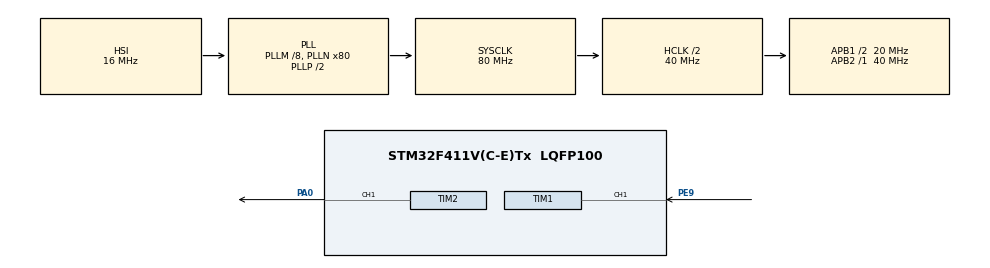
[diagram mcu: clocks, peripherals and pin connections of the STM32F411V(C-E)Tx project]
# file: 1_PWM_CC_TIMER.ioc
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Mcu.Family=STM32F4
PC15-OSC32_OUT.Mode=LSE-External-Oscillator
RCC.CortexFreq_Value=40000000
RCC.APB1CLKDivider=RCC_HCLK_DIV2
PC14-OSC32_IN.Signal=RCC_OSC32_IN
RCC.SYSCLKSource=RCC_SYSCLKSOURCE_PLLCLK
ProjectManager.StackSize=0x400
PA0-WKUP.Signal=S_TIM2_CH1_ETR
TIM2.Pulse-PWM\ Generation1\ CH1=500
PA13.Signal=SYS_JTMS-SWDIO
TIM1.Prescaler=40
SH.S_TIM1_CH1.0=TIM1_CH1,Input_Capture1_from_TI1
ProjectManager.TargetToolchain=STM32CubeIDE
RCC.HCLKFreq_Value=40000000
RCC.APB2TimFreq_Value=40000000
PC15-OSC32_OUT.Signal=RCC_OSC32_OUT
RCC.AHBFreq_Value=40000000
RCC.HSE_VALUE=8000000
board=STM32F411E-DISCO
RCC.VCOOutputFreq_Value=160000000
RCC.APB2Freq_Value=40000000
PC14-OSC32_IN.Mode=LSE-External-Oscillator
VP_TIM2_VS_ClockSourceINT.Mode=Internal
PE9.Signal=S_TIM1_CH1
PA14.Mode=Serial_Wire
RCC.AHBCLKDivider=RCC_SYSCLK_DIV2
TIM2.Channel-PWM\ Generation1\ CH1=TIM_CHANNEL_1
TIM2.Period=999
PA13.Mode=Serial_Wire
Mcu.Name=STM32F411V(C-E)Tx
VP_TIM1_VS_ClockSourceINT.Mode=Internal
NVIC.TIM1_CC_IRQn=true\:0\:0\:false\:false\:true\:true\:true
RCC.48MHZClocksFreq_Value=20000000
RCC.SYSCLKFreq_VALUE=80000000
Mcu.Package=LQFP100
TIM2.Prescaler=0
TIM1.Channel-Input_Capture1_from_TI1=TIM_CHANNEL_1
SH.S_TIM2_CH1_ETR.0=TIM2_CH1,PWM Generation1 CH1
PA14.Signal=SYS_JTCK-SWCLK
ProjectManager.HeapSize=0x200
RCC.HSI_VALUE=16000000
RCC.PLLQ=8
NVIC.PriorityGroup=NVIC_PRIORITYGROUP_0
RCC.PLLM=8
RCC.PLLN=80
RCC.APB1TimFreq_Value=40000000
TIM1.ICPolarity_CH1=TIM_INPUTCHANNELPOLARITY_FALLING
TIM1.Period=0xffff
RCC.APB1Freq_Value=20000000
RCC.PLLI2SN=200
RCC.PLLI2SM=5

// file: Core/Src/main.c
/* USER CODE BEGIN Header */
/**
  ******************************************************************************
  * @file           : main.c
  * @brief          : Main program body
  ******************************************************************************
  * @attention
  *
  * <h2><center>&copy; Copyright (c) 2021 STMicroelectronics.
  * All rights reserved.</center></h2>
  *
  * This software component is licensed by ST under Ultimate Liberty license
  * SLA0044, the "License"; You may not use this file except in compliance with
  * the License. You may obtain a copy of the License at:
  *                             www.st.com/SLA0044
  *
  ******************************************************************************
  */
/* USER CODE END Header */
#include "main.h"

TIM_HandleTypeDef htim1;
TIM_HandleTypeDef htim2;

/* USER CODE BEGIN PV */
	uint16_t icValue = 0;
	uint16_t preIcValue = 0;
	uint16_t T = 0;
	uint16_t f = 0;
	uint8_t firstEdge = 0;
/* USER CODE END PV */

void SystemClock_Config(void);
static void MX_GPIO_Init(void);
static void MX_TIM1_Init(void);
static void MX_TIM2_Init(void);

/* USER CODE BEGIN 0 */
void HAL_TIM_IC_CaptureCallback(TIM_HandleTypeDef *htim)
{
	icValue = __HAL_TIM_GET_COMPARE(&htim1,TIM_CHANNEL_1);
	if(firstEdge ==0 )
	{
		preIcValue = icValue;
		firstEdge++;
	}
	else if(firstEdge == 1)
	{
		T = icValue - preIcValue;
		f = 1000000/T;
		firstEdge = 0;
		HAL_TIM_IC_Stop_IT(&htim1, TIM_CHANNEL_1);
	}

//	preIcValue = icValue;
	//1MHZ clock = > T xung => t us
}
void dutyScale()
{
	//1Khz => 1% <=> 10
	for(unsigned short duty = 0; duty <= 100; duty++)
	{
		__HAL_TIM_SET_COMPARE(&htim2,TIM_CHANNEL_1,10*duty);
		HAL_Delay(100);
	}
}
void getPulseFreq()
{
	  HAL_TIM_IC_Start_IT(&htim1, TIM_CHANNEL_1);
}
/* USER CODE END 0 */

int main(void)
{

  /* MCU Configuration--------------------------------------------------------*/

  /* Reset of all peripherals, Initializes the Flash interface and the Systick. */
  HAL_Init();

  /* Configure the system clock */
  SystemClock_Config();

  /* Initialize all configured peripherals */
  MX_GPIO_Init();
  MX_TIM1_Init();
  MX_TIM2_Init();
  /* USER CODE BEGIN 2 */
  HAL_TIM_PWM_Start(&htim2, TIM_CHANNEL_1);
  HAL_TIM_IC_Start_IT(&htim1, TIM_CHANNEL_1);
  /* USER CODE END 2 */

  /* Infinite loop */
  while (1)
  {

  }
}

void SystemClock_Config(void)
{
  RCC_OscInitTypeDef RCC_OscInitStruct = {0};
  RCC_ClkInitTypeDef RCC_ClkInitStruct = {0};

  /** Configure the main internal regulator output voltage
  */
  __HAL_RCC_PWR_CLK_ENABLE();
  __HAL_PWR_VOLTAGESCALING_CONFIG(PWR_REGULATOR_VOLTAGE_SCALE1);
  /** Initializes the RCC Oscillators according to the specified parameters
  * in the RCC_OscInitTypeDef structure.
  */
  RCC_OscInitStruct.OscillatorType = RCC_OSCILLATORTYPE_HSI;
  RCC_OscInitStruct.HSIState = RCC_HSI_ON;
  RCC_OscInitStruct.HSICalibrationValue = RCC_HSICALIBRATION_DEFAULT;
  RCC_OscInitStruct.PLL.PLLState = RCC_PLL_ON;
  RCC_OscInitStruct.PLL.PLLSource = RCC_PLLSOURCE_HSI;
  RCC_OscInitStruct.PLL.PLLM = 8;
  RCC_OscInitStruct.PLL.PLLN = 80;
  RCC_OscInitStruct.PLL.PLLP = RCC_PLLP_DIV2;
  RCC_OscInitStruct.PLL.PLLQ = 8;
  if (HAL_RCC_OscConfig(&RCC_OscInitStruct) != HAL_OK)
  {
    Error_Handler();
  }
  /** Initializes the CPU, AHB and APB buses clocks
  */
  RCC_ClkInitStruct.ClockType = RCC_CLOCKTYPE_HCLK|RCC_CLOCKTYPE_SYSCLK
                              |RCC_CLOCKTYPE_PCLK1|RCC_CLOCKTYPE_PCLK2;
  RCC_ClkInitStruct.SYSCLKSource = RCC_SYSCLKSOURCE_PLLCLK;
  RCC_ClkInitStruct.AHBCLKDivider = RCC_SYSCLK_DIV2;
  RCC_ClkInitStruct.APB1CLKDivider = RCC_HCLK_DIV2;
  RCC_ClkInitStruct.APB2CLKDivider = RCC_HCLK_DIV1;

  if (HAL_RCC_ClockConfig(&RCC_ClkInitStruct, FLASH_LATENCY_1) != HAL_OK)
  {
    Error_Handler();
  }
}

static void MX_TIM1_Init(void)
{

  TIM_ClockConfigTypeDef sClockSourceConfig = {0};
  TIM_MasterConfigTypeDef sMasterConfig = {0};
  TIM_IC_InitTypeDef sConfigIC = {0};

  htim1.Instance = TIM1;
  htim1.Init.Prescaler = 40;
  htim1.Init.CounterMode = TIM_COUNTERMODE_UP;
  htim1.Init.Period = 0xffff;
  htim1.Init.ClockDivision = TIM_CLOCKDIVISION_DIV1;
  htim1.Init.RepetitionCounter = 0;
  htim1.Init.AutoReloadPreload = TIM_AUTORELOAD_PRELOAD_DISABLE;
  if (HAL_TIM_Base_Init(&htim1) != HAL_OK)
  {
    Error_Handler();
  }
  sClockSourceConfig.ClockSource = TIM_CLOCKSOURCE_INTERNAL;
  if (HAL_TIM_ConfigClockSource(&htim1, &sClockSourceConfig) != HAL_OK)
  {
    Error_Handler();
  }
  if (HAL_TIM_IC_Init(&htim1) != HAL_OK)
  {
    Error_Handler();
  }
  sMasterConfig.MasterOutputTrigger = TIM_TRGO_RESET;
  sMasterConfig.MasterSlaveMode = TIM_MASTERSLAVEMODE_DISABLE;
  if (HAL_TIMEx_MasterConfigSynchronization(&htim1, &sMasterConfig) != HAL_OK)
  {
    Error_Handler();
  }
  sConfigIC.ICPolarity = TIM_INPUTCHANNELPOLARITY_FALLING;
  sConfigIC.ICSelection = TIM_ICSELECTION_DIRECTTI;
  sConfigIC.ICPrescaler = TIM_ICPSC_DIV1;
  sConfigIC.ICFilter = 0;
  if (HAL_TIM_IC_ConfigChannel(&htim1, &sConfigIC, TIM_CHANNEL_1) != HAL_OK)
  {
    Error_Handler();
  }

}

static void MX_TIM2_Init(void)
{

  TIM_ClockConfigTypeDef sClockSourceConfig = {0};
  TIM_MasterConfigTypeDef sMasterConfig = {0};
  TIM_OC_InitTypeDef sConfigOC = {0};

  htim2.Instance = TIM2;
  htim2.Init.Prescaler = 0;
  htim2.Init.CounterMode = TIM_COUNTERMODE_UP;
  htim2.Init.Period = 999;
  htim2.Init.ClockDivision = TIM_CLOCKDIVISION_DIV1;
  htim2.Init.AutoReloadPreload = TIM_AUTORELOAD_PRELOAD_DISABLE;
  if (HAL_TIM_Base_Init(&htim2) != HAL_OK)
  {
    Error_Handler();
  }
  sClockSourceConfig.ClockSource = TIM_CLOCKSOURCE_INTERNAL;
  if (HAL_TIM_ConfigClockSource(&htim2, &sClockSourceConfig) != HAL_OK)
  {
    Error_Handler();
  }
  if (HAL_TIM_PWM_Init(&htim2) != HAL_OK)
  {
    Error_Handler();
  }
  sMasterConfig.MasterOutputTrigger = TIM_TRGO_RESET;
  sMasterConfig.MasterSlaveMode = TIM_MASTERSLAVEMODE_DISABLE;
  if (HAL_TIMEx_MasterConfigSynchronization(&htim2, &sMasterConfig) != HAL_OK)
  {
    Error_Handler();
  }
  sConfigOC.OCMode = TIM_OCMODE_PWM1;
  sConfigOC.Pulse = 500;
  sConfigOC.OCPolarity = TIM_OCPOLARITY_HIGH;
  sConfigOC.OCFastMode = TIM_OCFAST_DISABLE;
  if (HAL_TIM_PWM_ConfigChannel(&htim2, &sConfigOC, TIM_CHANNEL_1) != HAL_OK)
  {
    Error_Handler();
  }
  HAL_TIM_MspPostInit(&htim2);

}

static void MX_GPIO_Init(void)
{

  /* GPIO Ports Clock Enable */
  __HAL_RCC_GPIOC_CLK_ENABLE();
  __HAL_RCC_GPIOA_CLK_ENABLE();
  __HAL_RCC_GPIOE_CLK_ENABLE();

}

void Error_Handler(void)
{
  __disable_irq();
  while (1)
  {
  }
}

/************************ (C) COPYRIGHT STMicroelectronics *****END OF FILE****/
